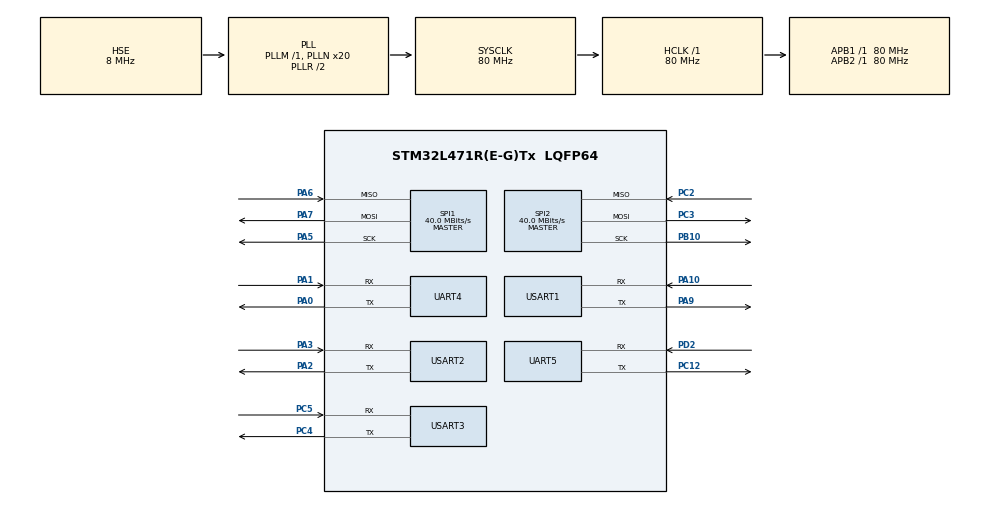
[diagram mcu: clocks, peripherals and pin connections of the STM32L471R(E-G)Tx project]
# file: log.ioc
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FREERTOS.Tasks01=defaultTask,24,128,StartDefaultTask,Default,NULL
Mcu.Family=STM32L4
Mcu.Name=STM32L471R(E-G)Tx
Mcu.Package=LQFP64
NVIC.PriorityGroup=NVIC_PRIORITYGROUP_4
PA0.Mode=Asynchronous
PA0.Signal=UART4_TX
PA1.Mode=Asynchronous
PA1.Signal=UART4_RX
PA10.Mode=Asynchronous
PA10.Signal=USART1_RX
PA2.Mode=Asynchronous
PA2.Signal=USART2_TX
PA3.Mode=Asynchronous
PA3.Signal=USART2_RX
PA5.Mode=Full_Duplex_Master
PA5.Signal=SPI1_SCK
PA6.Mode=Full_Duplex_Master
PA6.Signal=SPI1_MISO
PA7.Mode=Full_Duplex_Master
PA7.Signal=SPI1_MOSI
PA9.Mode=Asynchronous
PA9.Signal=USART1_TX
PB10.Mode=Full_Duplex_Master
PB10.Signal=SPI2_SCK
PC12.Mode=Asynchronous
PC12.Signal=UART5_TX
PC14-OSC32_IN\ (PC14).Mode=LSE-External-Oscillator
PC14-OSC32_IN\ (PC14).Signal=RCC_OSC32_IN
PC15-OSC32_OUT\ (PC15).Mode=LSE-External-Oscillator
PC15-OSC32_OUT\ (PC15).Signal=RCC_OSC32_OUT
PC2.Mode=Full_Duplex_Master
PC2.Signal=SPI2_MISO
PC3.Mode=Full_Duplex_Master
PC3.Signal=SPI2_MOSI
PC4.Mode=Asynchronous
PC4.Signal=USART3_TX
PC5.Mode=Asynchronous
PC5.Signal=USART3_RX
PD2.Mode=Asynchronous
PD2.Signal=UART5_RX
PH0-OSC_IN\ (PH0).Mode=HSE-External-Oscillator
PH0-OSC_IN\ (PH0).Signal=RCC_OSC_IN
PH1-OSC_OUT\ (PH1).Mode=HSE-External-Oscillator
PH1-OSC_OUT\ (PH1).Signal=RCC_OSC_OUT
ProjectManager.HeapSize=0x200
ProjectManager.StackSize=0x400
ProjectManager.TargetToolchain=STM32CubeIDE
RCC.ADCFreq_Value=32000000
RCC.AHBFreq_Value=80000000
RCC.APB1Freq_Value=80000000
RCC.APB1TimFreq_Value=80000000
RCC.APB2Freq_Value=80000000
RCC.APB2TimFreq_Value=80000000
RCC.CortexFreq_Value=80000000
RCC.HCLKFreq_Value=80000000
RCC.HSE_VALUE=8000000
RCC.HSI_VALUE=16000000
RCC.MSI_VALUE=4000000
RCC.PLLN=20
RCC.PLLSourceVirtual=RCC_PLLSOURCE_HSE
RCC.RTCClockSelection=RCC_RTCCLKSOURCE_LSE
RCC.SYSCLKFreq_VALUE=80000000
RCC.SYSCLKSource=RCC_SYSCLKSOURCE_PLLCLK
RCC.VCOOutputFreq_Value=160000000
SPI1.BaudRatePrescaler=SPI_BAUDRATEPRESCALER_2
SPI1.CalculateBaudRate=40.0 MBits/s
SPI1.Direction=SPI_DIRECTION_2LINES
SPI1.Mode=SPI_MODE_MASTER
SPI1.VirtualType=VM_MASTER
SPI2.BaudRatePrescaler=SPI_BAUDRATEPRESCALER_2
SPI2.CalculateBaudRate=40.0 MBits/s
SPI2.Direction=SPI_DIRECTION_2LINES
SPI2.Mode=SPI_MODE_MASTER
SPI2.VirtualType=VM_MASTER
USART1.VirtualMode-Asynchronous=VM_ASYNC
USART2.VirtualMode-Asynchronous=VM_ASYNC
USART3.VirtualMode-Asynchronous=VM_ASYNC
VP_FREERTOS_VS_CMSIS_V2.Mode=CMSIS_V2
VP_RTC_VS_RTC_Activate.Mode=RTC_Enabled
VP_TIM1_VS_OPM.Mode=OPM_bit
VP_TIM7_VS_ClockSourceINT.Mode=Enable_Timer
board=custom

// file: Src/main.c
/* USER CODE BEGIN Header */
/**
 ******************************************************************************
 * @file           : main.c
 * @brief          : Main program body
 ******************************************************************************
 * @attention
 *
 * <h2><center>&copy; Copyright (c) 2019 STMicroelectronics.
 * All rights reserved.</center></h2>
 *
 * This software component is licensed by ST under BSD 3-Clause license,
 * the "License"; You may not use this file except in compliance with the
 * License. You may obtain a copy of the License at:
 *                        opensource.org/licenses/BSD-3-Clause
 *
 ******************************************************************************
 */
/* USER CODE END Header */

#include "main.h"
#include "cmsis_os.h"
#include "stdio.h"

/* USER CODE BEGIN Includes */
#define	TAG	"main"
/* USER CODE END Includes */

/* USER CODE BEGIN PTD */
extern UART_HandleTypeDef huart1;
extern void
serial1_hal_init(void);
#define HAL_Debug_init serial1_hal_init
/* USER CODE END PTD */

RTC_HandleTypeDef hrtc;

SPI_HandleTypeDef hspi1;
SPI_HandleTypeDef hspi2;

TIM_HandleTypeDef htim1;
TIM_HandleTypeDef htim7;

UART_HandleTypeDef huart4;
UART_HandleTypeDef huart5;
UART_HandleTypeDef huart1;
UART_HandleTypeDef huart2;
UART_HandleTypeDef huart3;

osThreadId_t defaultTaskHandle;

void SystemClock_Config(void);
static void MX_GPIO_Init(void);
static void MX_RTC_Init(void);
static void MX_SPI1_Init(void);
static void MX_SPI2_Init(void);
static void MX_TIM1_Init(void);
static void MX_TIM7_Init(void);
static void MX_UART4_Init(void);
static void MX_UART5_Init(void);
static void MX_USART1_UART_Init(void);
static void MX_USART2_UART_Init(void);
static void MX_USART3_UART_Init(void);
void StartDefaultTask(void *argument);

int main(void)
{

	/* MCU Configuration--------------------------------------------------------*/

	/* Reset of all peripherals, Initializes the Flash interface and the Systick. */
	HAL_Init();

	/* Configure the system clock */
	SystemClock_Config();

	/* USER CODE BEGIN SysInit */
	//HAL_Debug_init();
	/* USER CODE END SysInit */

	/* Initialize all configured peripherals */
	MX_GPIO_Init();
	MX_RTC_Init();
	MX_SPI1_Init();
	MX_SPI2_Init();
	MX_TIM1_Init();
	MX_TIM7_Init();
	MX_UART4_Init();
	MX_UART5_Init();
	MX_USART1_UART_Init();
	MX_USART2_UART_Init();
	MX_USART3_UART_Init();
	/* USER CODE BEGIN 2 */
	//CYT_LOGE(TAG, "start up task\n");
	//CYT_LOGW(TAG, "start up task\n");
	//CYT_LOGI(TAG, "start up task\n");
	//CYT_LOGD(TAG, "start up task\n");
	/* USER CODE END 2 */

	osKernelInitialize();

	/* Create the thread(s) */
	/* definition and creation of defaultTask */
	const osThreadAttr_t defaultTask_attributes =
	{ .name = "defaultTask", .priority = (osPriority_t) osPriorityNormal,
			.stack_size = 128 };
	defaultTaskHandle = osThreadNew(StartDefaultTask, NULL,
			&defaultTask_attributes);

	/* Start scheduler */
	osKernelStart();

	/* We should never get here as control is now taken by the scheduler */

	/* Infinite loop */
	while (1)
	{

	}
}

void SystemClock_Config(void)
{
	RCC_OscInitTypeDef RCC_OscInitStruct =
	{ 0 };
	RCC_ClkInitTypeDef RCC_ClkInitStruct =
	{ 0 };
	RCC_PeriphCLKInitTypeDef PeriphClkInit =
	{ 0 };

	/** Configure LSE Drive Capability
	 */
	HAL_PWR_EnableBkUpAccess();
	__HAL_RCC_LSEDRIVE_CONFIG(RCC_LSEDRIVE_LOW);
	/** Initializes the CPU, AHB and APB busses clocks
	 */
	RCC_OscInitStruct.OscillatorType = RCC_OSCILLATORTYPE_HSE
			| RCC_OSCILLATORTYPE_LSE;
	RCC_OscInitStruct.HSEState = RCC_HSE_ON;
	RCC_OscInitStruct.LSEState = RCC_LSE_ON;
	RCC_OscInitStruct.PLL.PLLState = RCC_PLL_ON;
	RCC_OscInitStruct.PLL.PLLSource = RCC_PLLSOURCE_HSE;
	RCC_OscInitStruct.PLL.PLLM = 1;
	RCC_OscInitStruct.PLL.PLLN = 20;
	RCC_OscInitStruct.PLL.PLLP = RCC_PLLP_DIV7;
	RCC_OscInitStruct.PLL.PLLQ = RCC_PLLQ_DIV2;
	RCC_OscInitStruct.PLL.PLLR = RCC_PLLR_DIV2;
	if (HAL_RCC_OscConfig(&RCC_OscInitStruct) != HAL_OK)
	{
		Error_Handler();
	}
	/** Initializes the CPU, AHB and APB busses clocks
	 */
	RCC_ClkInitStruct.ClockType = RCC_CLOCKTYPE_HCLK | RCC_CLOCKTYPE_SYSCLK
			| RCC_CLOCKTYPE_PCLK1 | RCC_CLOCKTYPE_PCLK2;
	RCC_ClkInitStruct.SYSCLKSource = RCC_SYSCLKSOURCE_PLLCLK;
	RCC_ClkInitStruct.AHBCLKDivider = RCC_SYSCLK_DIV1;
	RCC_ClkInitStruct.APB1CLKDivider = RCC_HCLK_DIV1;
	RCC_ClkInitStruct.APB2CLKDivider = RCC_HCLK_DIV1;

	if (HAL_RCC_ClockConfig(&RCC_ClkInitStruct, FLASH_LATENCY_4) != HAL_OK)
	{
		Error_Handler();
	}
	PeriphClkInit.PeriphClockSelection = RCC_PERIPHCLK_RTC
			| RCC_PERIPHCLK_USART1 | RCC_PERIPHCLK_USART2 | RCC_PERIPHCLK_USART3
			| RCC_PERIPHCLK_UART4 | RCC_PERIPHCLK_UART5;
	PeriphClkInit.Usart1ClockSelection = RCC_USART1CLKSOURCE_PCLK2;
	PeriphClkInit.Usart2ClockSelection = RCC_USART2CLKSOURCE_PCLK1;
	PeriphClkInit.Usart3ClockSelection = RCC_USART3CLKSOURCE_PCLK1;
	PeriphClkInit.Uart4ClockSelection = RCC_UART4CLKSOURCE_PCLK1;
	PeriphClkInit.Uart5ClockSelection = RCC_UART5CLKSOURCE_PCLK1;
	PeriphClkInit.RTCClockSelection = RCC_RTCCLKSOURCE_LSE;
	if (HAL_RCCEx_PeriphCLKConfig(&PeriphClkInit) != HAL_OK)
	{
		Error_Handler();
	}
	/** Configure the main internal regulator output voltage
	 */
	if (HAL_PWREx_ControlVoltageScaling(PWR_REGULATOR_VOLTAGE_SCALE1) != HAL_OK)
	{
		Error_Handler();
	}
}

static void MX_RTC_Init(void)
{

	/** Initialize RTC Only
	 */
	hrtc.Instance = RTC;
	hrtc.Init.HourFormat = RTC_HOURFORMAT_24;
	hrtc.Init.AsynchPrediv = 127;
	hrtc.Init.SynchPrediv = 255;
	hrtc.Init.OutPut = RTC_OUTPUT_DISABLE;
	hrtc.Init.OutPutRemap = RTC_OUTPUT_REMAP_NONE;
	hrtc.Init.OutPutPolarity = RTC_OUTPUT_POLARITY_HIGH;
	hrtc.Init.OutPutType = RTC_OUTPUT_TYPE_OPENDRAIN;
	if (HAL_RTC_Init(&hrtc) != HAL_OK)
	{
		Error_Handler();
	}

}

static void MX_SPI1_Init(void)
{

	/* SPI1 parameter configuration*/
	hspi1.Instance = SPI1;
	hspi1.Init.Mode = SPI_MODE_MASTER;
	hspi1.Init.Direction = SPI_DIRECTION_2LINES;
	hspi1.Init.DataSize = SPI_DATASIZE_4BIT;
	hspi1.Init.CLKPolarity = SPI_POLARITY_LOW;
	hspi1.Init.CLKPhase = SPI_PHASE_1EDGE;
	hspi1.Init.NSS = SPI_NSS_SOFT;
	hspi1.Init.BaudRatePrescaler = SPI_BAUDRATEPRESCALER_2;
	hspi1.Init.FirstBit = SPI_FIRSTBIT_MSB;
	hspi1.Init.TIMode = SPI_TIMODE_DISABLE;
	hspi1.Init.CRCCalculation = SPI_CRCCALCULATION_DISABLE;
	hspi1.Init.CRCPolynomial = 7;
	hspi1.Init.CRCLength = SPI_CRC_LENGTH_DATASIZE;
	hspi1.Init.NSSPMode = SPI_NSS_PULSE_ENABLE;
	if (HAL_SPI_Init(&hspi1) != HAL_OK)
	{
		Error_Handler();
	}

}

static void MX_SPI2_Init(void)
{

	/* SPI2 parameter configuration*/
	hspi2.Instance = SPI2;
	hspi2.Init.Mode = SPI_MODE_MASTER;
	hspi2.Init.Direction = SPI_DIRECTION_2LINES;
	hspi2.Init.DataSize = SPI_DATASIZE_4BIT;
	hspi2.Init.CLKPolarity = SPI_POLARITY_LOW;
	hspi2.Init.CLKPhase = SPI_PHASE_1EDGE;
	hspi2.Init.NSS = SPI_NSS_SOFT;
	hspi2.Init.BaudRatePrescaler = SPI_BAUDRATEPRESCALER_2;
	hspi2.Init.FirstBit = SPI_FIRSTBIT_MSB;
	hspi2.Init.TIMode = SPI_TIMODE_DISABLE;
	hspi2.Init.CRCCalculation = SPI_CRCCALCULATION_DISABLE;
	hspi2.Init.CRCPolynomial = 7;
	hspi2.Init.CRCLength = SPI_CRC_LENGTH_DATASIZE;
	hspi2.Init.NSSPMode = SPI_NSS_PULSE_ENABLE;
	if (HAL_SPI_Init(&hspi2) != HAL_OK)
	{
		Error_Handler();
	}

}

static void MX_TIM1_Init(void)
{

	htim1.Instance = TIM1;
	htim1.Init.Prescaler = 0;
	htim1.Init.CounterMode = TIM_COUNTERMODE_UP;
	htim1.Init.Period = 0;
	htim1.Init.ClockDivision = TIM_CLOCKDIVISION_DIV1;
	htim1.Init.RepetitionCounter = 0;
	htim1.Init.AutoReloadPreload = TIM_AUTORELOAD_PRELOAD_DISABLE;
	if (HAL_TIM_OnePulse_Init(&htim1, TIM_OPMODE_SINGLE) != HAL_OK)
	{
		Error_Handler();
	}

}

static void MX_TIM7_Init(void)
{

	TIM_MasterConfigTypeDef sMasterConfig =
	{ 0 };

	htim7.Instance = TIM7;
	htim7.Init.Prescaler = 0;
	htim7.Init.CounterMode = TIM_COUNTERMODE_UP;
	htim7.Init.Period = 0;
	htim7.Init.AutoReloadPreload = TIM_AUTORELOAD_PRELOAD_DISABLE;
	if (HAL_TIM_Base_Init(&htim7) != HAL_OK)
	{
		Error_Handler();
	}
	sMasterConfig.MasterOutputTrigger = TIM_TRGO_RESET;
	sMasterConfig.MasterSlaveMode = TIM_MASTERSLAVEMODE_DISABLE;
	if (HAL_TIMEx_MasterConfigSynchronization(&htim7, &sMasterConfig) != HAL_OK)
	{
		Error_Handler();
	}

}

static void MX_UART4_Init(void)
{

	huart4.Instance = UART4;
	huart4.Init.BaudRate = 115200;
	huart4.Init.WordLength = UART_WORDLENGTH_8B;
	huart4.Init.StopBits = UART_STOPBITS_1;
	huart4.Init.Parity = UART_PARITY_NONE;
	huart4.Init.Mode = UART_MODE_TX_RX;
	huart4.Init.HwFlowCtl = UART_HWCONTROL_NONE;
	huart4.Init.OverSampling = UART_OVERSAMPLING_16;
	huart4.Init.OneBitSampling = UART_ONE_BIT_SAMPLE_DISABLE;
	huart4.AdvancedInit.AdvFeatureInit = UART_ADVFEATURE_NO_INIT;
	if (HAL_UART_Init(&huart4) != HAL_OK)
	{
		Error_Handler();
	}

}

static void MX_UART5_Init(void)
{

	huart5.Instance = UART5;
	huart5.Init.BaudRate = 115200;
	huart5.Init.WordLength = UART_WORDLENGTH_8B;
	huart5.Init.StopBits = UART_STOPBITS_1;
	huart5.Init.Parity = UART_PARITY_NONE;
	huart5.Init.Mode = UART_MODE_TX_RX;
	huart5.Init.HwFlowCtl = UART_HWCONTROL_NONE;
	huart5.Init.OverSampling = UART_OVERSAMPLING_16;
	huart5.Init.OneBitSampling = UART_ONE_BIT_SAMPLE_DISABLE;
	huart5.AdvancedInit.AdvFeatureInit = UART_ADVFEATURE_NO_INIT;
	if (HAL_UART_Init(&huart5) != HAL_OK)
	{
		Error_Handler();
	}

}

static void MX_USART1_UART_Init(void)
{

	huart1.Instance = USART1;
	huart1.Init.BaudRate = 115200;
	huart1.Init.WordLength = UART_WORDLENGTH_8B;
	huart1.Init.StopBits = UART_STOPBITS_1;
	huart1.Init.Parity = UART_PARITY_NONE;
	huart1.Init.Mode = UART_MODE_TX_RX;
	huart1.Init.HwFlowCtl = UART_HWCONTROL_NONE;
	huart1.Init.OverSampling = UART_OVERSAMPLING_16;
	huart1.Init.OneBitSampling = UART_ONE_BIT_SAMPLE_DISABLE;
	huart1.AdvancedInit.AdvFeatureInit = UART_ADVFEATURE_NO_INIT;
	if (HAL_UART_Init(&huart1) != HAL_OK)
	{
		Error_Handler();
	}

}

static void MX_USART2_UART_Init(void)
{

	huart2.Instance = USART2;
	huart2.Init.BaudRate = 115200;
	huart2.Init.WordLength = UART_WORDLENGTH_8B;
	huart2.Init.StopBits = UART_STOPBITS_1;
	huart2.Init.Parity = UART_PARITY_NONE;
	huart2.Init.Mode = UART_MODE_TX_RX;
	huart2.Init.HwFlowCtl = UART_HWCONTROL_NONE;
	huart2.Init.OverSampling = UART_OVERSAMPLING_16;
	huart2.Init.OneBitSampling = UART_ONE_BIT_SAMPLE_DISABLE;
	huart2.AdvancedInit.AdvFeatureInit = UART_ADVFEATURE_NO_INIT;
	if (HAL_UART_Init(&huart2) != HAL_OK)
	{
		Error_Handler();
	}

}

static void MX_USART3_UART_Init(void)
{

	huart3.Instance = USART3;
	huart3.Init.BaudRate = 115200;
	huart3.Init.WordLength = UART_WORDLENGTH_8B;
	huart3.Init.StopBits = UART_STOPBITS_1;
	huart3.Init.Parity = UART_PARITY_NONE;
	huart3.Init.Mode = UART_MODE_TX_RX;
	huart3.Init.HwFlowCtl = UART_HWCONTROL_NONE;
	huart3.Init.OverSampling = UART_OVERSAMPLING_16;
	huart3.Init.OneBitSampling = UART_ONE_BIT_SAMPLE_DISABLE;
	huart3.AdvancedInit.AdvFeatureInit = UART_ADVFEATURE_NO_INIT;
	if (HAL_UART_Init(&huart3) != HAL_OK)
	{
		Error_Handler();
	}

}

static void MX_GPIO_Init(void)
{

	/* GPIO Ports Clock Enable */
	__HAL_RCC_GPIOC_CLK_ENABLE()
	;
	__HAL_RCC_GPIOH_CLK_ENABLE()
	;
	__HAL_RCC_GPIOA_CLK_ENABLE()
	;
	__HAL_RCC_GPIOB_CLK_ENABLE()
	;
	__HAL_RCC_GPIOD_CLK_ENABLE()
	;

}

void StartDefaultTask(void *argument)
{

	/* USER CODE BEGIN 5 */
	/* Infinite loop */
	for (;;)
	{
		//CYT_LOGE(TAG, "start up task\n");
		printf("1");
		osDelay(1000);
	}
	/* USER CODE END 5 */
}

void Error_Handler(void)
{
}

/************************ (C) COPYRIGHT STMicroelectronics *****END OF FILE****/
